# GD32F3x0 register map
File version: 1.0
CPU: CM4 r2p1, little endian, MPU, no FPU, 4 interrupt priority bits
Registers are 32-bit, read-write, reset 0x0 unless marked. A register's access mark holds for its fields unless they carry their own. Offsets are from the block's base; [hi:lo] are bit positions; {n}, {i} and the like mark numbered series.

## DAC — Digital-to-analog converter
Base 0x40007400
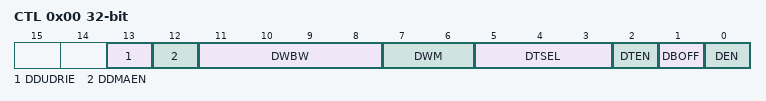
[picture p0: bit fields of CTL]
0x00 CTL — control register
  [13] DDUDRIE — DAC DMA underrun interrupt enable
  [12] DDMAEN — DAC DMA enable
  [11:8] DWBW — DAC noise wave bit width
  [7:6] DWM — DAC noise wave mode
  [5:3] DTSEL — DAC trigger selection
  [2] DTEN — DAC trigger enable
  [1] DBOFF — DAC output buffer disable
  [0] DEN — DAC enable
0x04 SWT wo — software trigger register
  [0] SWTR — DAC software trigger
0x08 DAC_R12DH — DAC 12-bit right-aligned data holding register
  [11:0] DAC_DH — DAC 12-bit right-aligned data
0x0C DAC_L12DH — DAC 12-bit left aligned data holding register
  [15:4] DAC_DH — DAC 12-bit left-aligned data
0x10 DAC_R8DH — DAC 8-bit right aligned data holding register
  [7:0] DAC_DH — DAC 8-bit right-aligned data
0x2C DAC_DO ro — DAC data output register
  [11:0] DAC_DO — DAC data output
0x34 STAT — status register
  [13] DDUDR — DAC DMA underrun flag

## DBG — Debug support
Base 0xE0042000
0x00 ID ro — MCU Device ID Code Register
  [31:0] ID_CODE — DBG ID code register
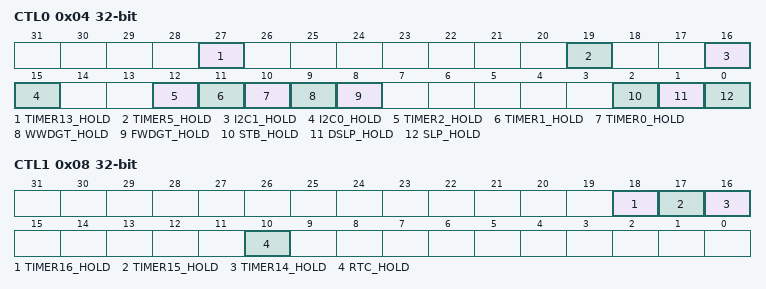
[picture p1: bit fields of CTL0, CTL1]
0x04 CTL0 — Debug Control Register 0
  [27] TIMER13_HOLD
  [19] TIMER5_HOLD
  [16] I2C1_HOLD
  [15] I2C0_HOLD
  [12] TIMER2_HOLD
  [11] TIMER1_HOLD
  [10] TIMER0_HOLD
  [9] WWDGT_HOLD
  [8] FWDGT_HOLD
  [2] STB_HOLD — Standby mode hold Mode
  [1] DSLP_HOLD — DEEPSLEEP mode hold Mode
  [0] SLP_HOLD — Sleep mode hold register
0x08 CTL1 — Debug Control Register 1
  [18] TIMER16_HOLD, [17] TIMER15_HOLD, [16] TIMER14_HOLD, [10] RTC_HOLD

## DMA — DMA controller
Base 0x40020000
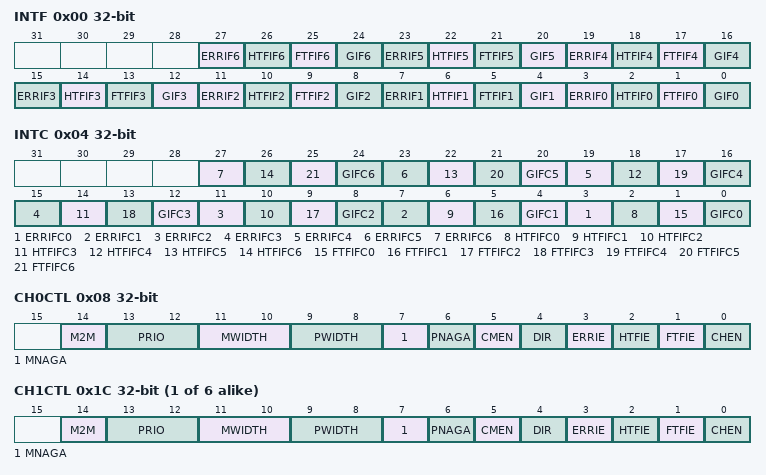
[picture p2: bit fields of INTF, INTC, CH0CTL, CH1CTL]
0x00 INTF ro — DMA interrupt flag register (DMA_INTF)
  [4n+3] ERRIF{n} (n=0..6) — Channel {n} Error flag
  [4n+2] HTFIF{n} (n=0..6) — Channel {n} Half Transfer Finish flag
  [4n+1] FTFIF{n} (n=0..6) — Channel {n} Full Transfer Finish flag
  [4n] GIF{n} (n=0..6) — Channel {n} Global interrupt flag
0x04 INTC wo — DMA interrupt flag clear register (DMA_INTC)
  [4n+3] ERRIFC{n} (n=0..6) — Channel {n} Error clear
  [4n+2] HTFIFC{n} (n=0..6) — Channel {n} Half Transfer clear
  [4n+1] FTFIFC{n} (n=0..6) — Channel {n} Full Transfer Finish clear
  [4n] GIFC{n} (n=0..6) — Channel {n} Global interrupt flag clear
0x08 CH0CTL — DMA channel configuration register (DMA_CH0CTL)
  [14] M2M — Memory to memory mode
  [13:12] PRIO — Priority Level of this channel
  [11:10] MWIDTH — Transfer data size of memory
  [9:8] PWIDTH — Transfer data size of peripheral
  [7] MNAGA — Next address generation algorithm of memory
  [6] PNAGA — Next address generation algorithm of peripheral
  [5] CMEN — Circular mode enable
  [4] DIR — Transfer direction
  [3] ERRIE — Transfer access error interrupt enable
  [2] HTFIE — Half Transfer Finish interrupt enable
  [1] FTFIE — Full Transfer Finish interrupt enable
  [0] CHEN — Channel enable
{0xC+0x14*i} CH{i}CNT (i=0..6) — DMA channel {i} counter register
  [15:0] CNT — Transfer counter
{0x10+0x14*i} CH{i}PADDR (i=0..6) — DMA channel {i} peripheral base address register
  [31:0] PADDR — Peripheral base address
{0x14+0x14*i} CH{i}MADDR (i=0..6) — DMA channel {i} memory base address register
  [31:0] MADDR — Memory address
{0x8+0x14*i} CH{i}CTL (i=1..6) — DMA channel configuration register (DMA_CH{i}CTL)
  [14] M2M — Memory to memory mode
  [13:12] PRIO — Priority Level of this channel
  [11:10] MWIDTH — Transfer data size of memory
  [9:8] PWIDTH — Transfer data size of peripheral
  [7] MNAGA — Next address generation algorithm of memory
  [6] PNAGA — Next address generation algorithm of peripheral
  [5] CMEN — Circular mode enable
  [4] DIR — Transfer direction
  [3] ERRIE — Error interrupt enable
  [2] HTFIE — Half Transfer Finish interrupt enable
  [1] FTFIE — Full Transfer Finish interrupt enable
  [0] CHEN — Channel enable
